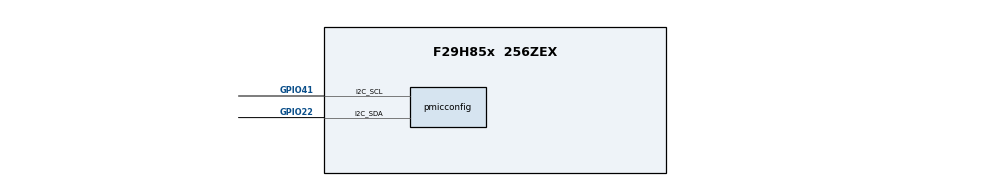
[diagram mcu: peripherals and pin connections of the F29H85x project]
/**
 * @cliArgs --device "F29H85x" --package "256ZEX" --part "F29H85x_256ZEX" --context "CPU1" --product "MCU_SDK_F29H85x@1.02.02.00"
 * @versions {"tool":"1.25.0+4237"}
 */

    
const divider15       = system.clockTree["PLL_REFDIV"];
divider15.divideValue = 1;

const multiplier1         = system.clockTree["PLL_IMULT"];
multiplier1.multiplyValue = 40;

const mux7       = system.clockTree["OSCCLKSRCSEL"];
mux7.inputSelect = "INTOSC2";

/**
 * Import the modules used in this configuration.
 */
const jtag          = scripting.addModule("/driverlib/jtag.js");
const pmicconfig    = scripting.addModule("/driverlib/pmicconfig.js");
const clock_c29_sdk = scripting.addModule("/kernel/dpl/clock_c29_sdk");

pmicconfig.Type                           = "TPS65036XX";
pmicconfig.pmici2c.targetAddress          = 0x60;
pmicconfig.pmici2c.i2c.$assign            = "I2CB";
pmicconfig.pmici2c.i2c.i2c_sdaPin.$assign = "GPIO22";
pmicconfig.pmici2c.i2c.i2c_sclPin.$assign = "GPIO41";
pmicconfig.pmici2c.periphClock.$name      = "driverlib_perClock1";
pmicconfig.pmici2c.periphConfig.$name     = "driverlib_perConfig0";

clock_c29_sdk.dplTimer.periphClock.pinmuxPeripheralModule = scripting.forceWrite("");
clock_c29_sdk.dplTimer.periphClock.$name                  = "driverlib_perClock0";

/**
 * Pinmux solution for unlocked pins/peripherals. This ensures that minor changes to the automatic solver in a future
 * version of the tool will not impact the pinmux you originally saw.  These lines can be completely deleted in order to
 * re-solve from scratch.
 */
jtag.JTAG.$suggestSolution        = "JTAG";
jtag.JTAG.tdoPin.$suggestSolution = "GPIO223/TDO";
jtag.JTAG.tdiPin.$suggestSolution = "GPIO222/TDI";
